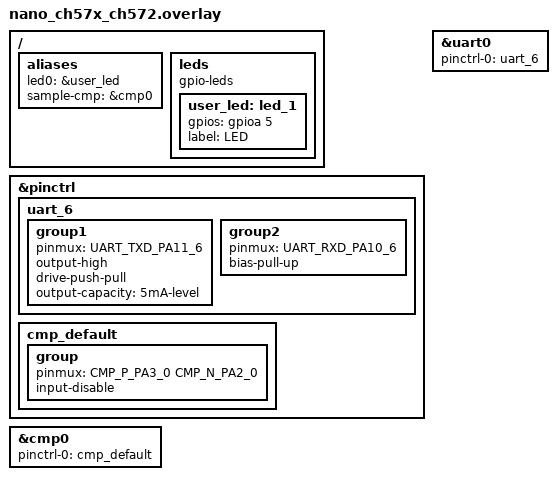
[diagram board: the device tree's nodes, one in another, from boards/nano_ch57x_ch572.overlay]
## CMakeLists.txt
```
# SPDX-License-Identifier: Apache-2.0

cmake_minimum_required(VERSION 3.20.0)
find_package(Zephyr REQUIRED HINTS $ENV{ZEPHYR_BASE})
project(comp_interrupt)

target_sources(app PRIVATE src/main.c)
```

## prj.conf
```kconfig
CONFIG_GPIO=y
CONFIG_COMPARATOR=y
```

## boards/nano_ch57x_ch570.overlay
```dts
/*
 * SPDX-FileCopyrightText: 2026 SMILE (smile.eu)
 *
 * SPDX-License-Identifier: Apache-2.0
 */

#include <zephyr/dt-bindings/pinctrl/ch570-pinctrl.h>

/ {
	aliases {
		led0 = &user_led;
		sample-cmp = &cmp0;
	};

	leds {
		compatible = "gpio-leds";

		user_led: led_1 {
			gpios = <&gpioa 5 GPIO_ACTIVE_HIGH>;
			label = "LED";
		};
	};
};

&pinctrl {
	uart_6: uart_6 {
		group1 {
			pinmux = <UART_TXD_PA11_6>;
			output-high;
			drive-push-pull;
			output-capacity = "5mA-level";
		};

		group2 {
			pinmux = <UART_RXD_PA10_6>;
			bias-pull-up;
		};
	};
};

&uart0 {
	pinctrl-0 = <&uart_6>;
};

&cmp0 {
	status = "okay";
};
```

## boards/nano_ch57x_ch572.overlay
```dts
/*
 * SPDX-FileCopyrightText: 2026 SMILE (smile.eu)
 *
 * SPDX-License-Identifier: Apache-2.0
 */

#include <zephyr/dt-bindings/pinctrl/ch570-pinctrl.h>

/ {
	aliases {
		led0 = &user_led;
		sample-cmp = &cmp0;
	};

	leds {
		compatible = "gpio-leds";

		user_led: led_1 {
			gpios = <&gpioa 5 GPIO_ACTIVE_HIGH>;
			label = "LED";
		};
	};
};

&pinctrl {
	uart_6: uart_6 {
		group1 {
			pinmux = <UART_TXD_PA11_6>;
			output-high;
			drive-push-pull;
			output-capacity = "5mA-level";
		};

		group2 {
			pinmux = <UART_RXD_PA10_6>;
			bias-pull-up;
		};
	};

	cmp_default: cmp_default {
		group {
			pinmux = <CMP_P_PA3_0 CMP_N_PA2_0>;
			input-disable;
		};
	};
};

&uart0 {
	pinctrl-0 = <&uart_6>;
};

&cmp0 {
	status = "okay";
	pinctrl-0 = <&cmp_default>;
	pinctrl-names = "default";
};
```

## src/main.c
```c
/*
 * SPDX-FileCopyrightText: 2026 SMILE (smile.eu)
 *
 * SPDX-License-Identifier: Apache-2.0
 */

#include <zephyr/kernel.h>
#include <zephyr/device.h>
#include <zephyr/drivers/gpio.h>
#include <zephyr/drivers/comparator.h>
#include <zephyr/drivers/comparator/comparator_wch_ch5xx.h>
#include <zephyr/sys/util.h>
#include <zephyr/sys/printk.h>
#include <inttypes.h>

#define SLEEP_TIME_MS 50

static struct gpio_dt_spec led = GPIO_DT_SPEC_GET_OR(DT_ALIAS(led0), gpios, {0});
static const struct device *cmp_dev = DEVICE_DT_GET(DT_ALIAS(sample_cmp));

static void comp_callback(const struct device *dev, void *user_data)
{
	printk("Rising edge detected at %" PRIu32 "\n", k_cycle_get_32());
}

int main(void)
{
	int ret;

	if (!device_is_ready(cmp_dev)) {
		printk("Error: comparator device %s is not ready\n", cmp_dev->name);
		return 0;
	}

	if (led.port && !gpio_is_ready_dt(&led)) {
		printk("Error: LED device %s is not ready; ignoring it\n", led.port->name);
		led.port = NULL;
	}

	if (led.port) {
		ret = gpio_pin_configure_dt(&led, GPIO_OUTPUT);
		if (ret != 0) {
			printk("Error %d: failed to configure LED device %s pin %d\n", ret,
			       led.port->name, led.pin);
			led.port = NULL;
		}
	}

	comparator_set_trigger(cmp_dev, COMPARATOR_TRIGGER_RISING_EDGE);
	comparator_set_trigger_callback(cmp_dev, comp_callback, NULL);

	printk("Starting comparator interrupt sample\n");
	printk("Change the voltage on the comparator input to toggle the LED state.\n");

	while (1) {
		int val = comparator_get_output(cmp_dev);

		gpio_pin_set_dt(&led, val);
		k_msleep(SLEEP_TIME_MS);
	}
}
```
